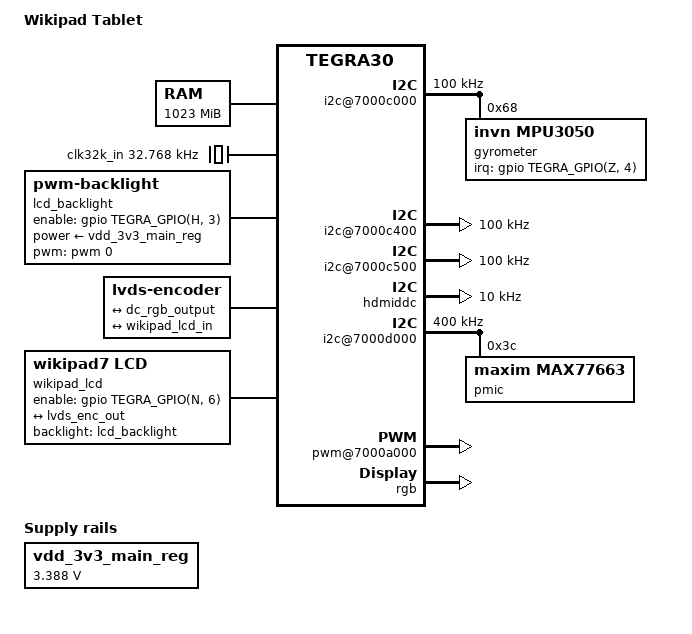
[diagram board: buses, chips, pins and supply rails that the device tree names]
// SPDX-License-Identifier: GPL-2.0
/dts-v1/;

#include "tegra30.dtsi"
#include <dt-bindings/mfd/max77620.h>
#include <dt-bindings/thermal/thermal.h>

/ {
	model = "Wikipad Tablet";
	compatible = "nvidia,wikipad", "nvidia,tegra30";

//	aliases {
//		rtc0 = "/i2c@7000d000/tps65911@2d";
//		rtc1 = "/rtc@7000e000";
//		serial0 = &uarta;
//	};

	chosen {
//		bootargs = "boot_delay=1000";
//		stdout-path = "serial0:115200n8";
	};

	firmware {
		trusted-foundations {
			compatible = "tlm,trusted-foundations";
			tlm,version-major = <2>;
			tlm,version-minor = <8>;
		};
	};

	memory@80000000 {
		reg = <0x80000000 0x3ff00000>;		// mem=1022M@2048M
	};

	clocks {
		compatible = "simple-bus";
		#address-cells = <1>;
		#size-cells = <0>;

		clk32k_in: clock@0 {
			compatible = "fixed-clock";
			reg = <0>;
			#clock-cells = <0>;
			clock-frequency = <32768>;
		};
	};

//	pcie@3000 {
//		status = "okay";
//
//		avdd-pexa-supply = <&ldo1_reg>;
//		vdd-pexa-supply = <&ldo1_reg>;
//		avdd-pexb-supply = <&ldo1_reg>;
//		vdd-pexb-supply = <&ldo1_reg>;
//		avdd-pex-pll-supply = <&ldo1_reg>;
//		avdd-plle-supply = <&ldo1_reg>;
//		vddio-pex-ctl-supply = <&sys_3v3_reg>;
//		hvdd-pex-supply = <&sys_3v3_pexs_reg>;
//
//		pci@1,0 {
//			status = "okay";
//			nvidia,num-lanes = <2>;
//		};
//
//		pci@2,0 {
//			nvidia,num-lanes = <2>;
//		};
//
//		pci@3,0 {
//			status = "okay";
//			nvidia,num-lanes = <2>;
//		};
//	};

// Copied from board-nabi2-pinmux
///////////////////////////////////
	pinmux@70000868 {
		pinctrl-names = "default";
		pinctrl-0 = <&state_default>;

		state_default: pinmux {
// SFIO
///////////////////////////////////
// SDMMC
////////////////
			sdmmc1_clk_pz0 {					// SD card slot
				nvidia,pins = "sdmmc1_clk_pz0";
				nvidia,function = "sdmmc1";
				nvidia,pull = <TEGRA_PIN_PULL_NONE>;
				nvidia,tristate = <TEGRA_PIN_DISABLE>;
				nvidia,enable-input = <TEGRA_PIN_ENABLE>;
			};
			sdmmc1_dat3_py4 {
				nvidia,pins = "sdmmc1_dat3_py4",
						"sdmmc1_dat2_py5",
						"sdmmc1_dat1_py6",
						"sdmmc1_dat0_py7",
						"sdmmc1_cmd_pz1";
				nvidia,function = "sdmmc1";
				nvidia,pull = <TEGRA_PIN_PULL_UP>;
				nvidia,tristate = <TEGRA_PIN_DISABLE>;
				nvidia,enable-input = <TEGRA_PIN_ENABLE>;
			};
			sdmmc3_clk_pa6 {					// Broadcom WLAN SDIO card
				nvidia,pins = "sdmmc3_clk_pa6";
				nvidia,function = "sdmmc3";
				nvidia,pull = <TEGRA_PIN_PULL_NONE>;
				nvidia,tristate = <TEGRA_PIN_DISABLE>;
				nvidia,enable-input = <TEGRA_PIN_ENABLE>;
			};
			sdmmc3_cmd_pa7 {
				nvidia,pins = "sdmmc3_cmd_pa7",
						"sdmmc3_dat0_pb7",
						"sdmmc3_dat1_pb6",
						"sdmmc3_dat2_pb5",
						"sdmmc3_dat3_pb4",
						"sdmmc3_dat6_pd3",
						"sdmmc3_dat7_pd4";		// GPIO: wlan_rst
				nvidia,function = "sdmmc3";
				nvidia,pull = <TEGRA_PIN_PULL_UP>;
				nvidia,tristate = <TEGRA_PIN_DISABLE>;
				nvidia,enable-input = <TEGRA_PIN_ENABLE>;
			};
			sdmmc4_clk_pcc4 {					// SSD
				nvidia,pins = "sdmmc4_clk_pcc4";
				nvidia,function = "sdmmc4";
				nvidia,pull = <TEGRA_PIN_PULL_NONE>;
				nvidia,tristate = <TEGRA_PIN_DISABLE>;
				nvidia,enable-input = <TEGRA_PIN_ENABLE>;
			};
			sdmmc4_rst_n_pcc3 {
				nvidia,pins = "sdmmc4_rst_n_pcc3";
				nvidia,function = "rsvd2";
				nvidia,pull = <TEGRA_PIN_PULL_DOWN>;
				nvidia,tristate = <TEGRA_PIN_DISABLE>;
				nvidia,enable-input = <TEGRA_PIN_ENABLE>;
			};
			sdmmc4_cmd_pt7 {
				nvidia,pins = "sdmmc4_cmd_pt7",
						"sdmmc4_dat0_paa0",
						"sdmmc4_dat1_paa1",
						"sdmmc4_dat2_paa2",
						"sdmmc4_dat3_paa3",
						"sdmmc4_dat4_paa4",
						"sdmmc4_dat5_paa5",
						"sdmmc4_dat6_paa6",
						"sdmmc4_dat7_paa7";
				nvidia,function = "sdmmc4";
				nvidia,pull = <TEGRA_PIN_PULL_UP>;
				nvidia,tristate = <TEGRA_PIN_DISABLE>;
				nvidia,enable-input = <TEGRA_PIN_ENABLE>;
			};
// I2C
////////////////
			gen1_i2c_scl_pc4 {					// I2C 1
				nvidia,pins = "gen1_i2c_scl_pc4",
						"gen1_i2c_sda_pc5";
				nvidia,function = "i2c1";
				nvidia,pull = <TEGRA_PIN_PULL_NONE>;
				nvidia,tristate = <TEGRA_PIN_DISABLE>;
				nvidia,enable-input = <TEGRA_PIN_ENABLE>;
				nvidia,open-drain = <TEGRA_PIN_ENABLE>;
			};
			gen2_i2c_scl_pt5 {					// I2C 2
				nvidia,pins = "gen2_i2c_scl_pt5",
						"gen2_i2c_sda_pt6";
				nvidia,function = "i2c2";
				nvidia,pull = <TEGRA_PIN_PULL_NONE>;
				nvidia,tristate = <TEGRA_PIN_DISABLE>;
				nvidia,enable-input = <TEGRA_PIN_ENABLE>;
				nvidia,open-drain = <TEGRA_PIN_ENABLE>;
			};
			cam_i2c_scl_pbb1 {					// I2C 3
				nvidia,pins = "cam_i2c_scl_pbb1",
						"cam_i2c_sda_pbb2";
				nvidia,function = "i2c3";
				nvidia,pull = <TEGRA_PIN_PULL_NONE>;
				nvidia,tristate = <TEGRA_PIN_DISABLE>;
				nvidia,enable-input = <TEGRA_PIN_ENABLE>;
				nvidia,open-drain = <TEGRA_PIN_ENABLE>;
			};
			ddc_scl_pv4 {						// I2C 4
				nvidia,pins = "ddc_scl_pv4",
						"ddc_sda_pv5";
				nvidia,function = "i2c4";
				nvidia,pull = <TEGRA_PIN_PULL_NONE>;
				nvidia,tristate = <TEGRA_PIN_DISABLE>;
				nvidia,enable-input = <TEGRA_PIN_ENABLE>;
				//nvidia,open-drain = <TEGRA_PIN_ENABLE>;	// I2C without open-drain????
			};
			pwr_i2c_scl_pz6 {					// I2C power
				nvidia,pins = "pwr_i2c_scl_pz6",
						"pwr_i2c_sda_pz7";
				nvidia,function = "i2cpwr";
				nvidia,pull = <TEGRA_PIN_PULL_NONE>;
				nvidia,tristate = <TEGRA_PIN_DISABLE>;
				nvidia,enable-input = <TEGRA_PIN_ENABLE>;
				nvidia,open-drain = <TEGRA_PIN_ENABLE>;
			};
// LCD
////////////////
			lcd_pclk_pb3 {
				nvidia,pins = "lcd_pclk_pb3",
						"lcd_de_pj1",
						"lcd_hsync_pj3",
						"lcd_vsync_pj4",
						"lcd_d0_pe0",
						"lcd_d1_pe1",
						"lcd_d2_pe2",
						"lcd_d3_pe3",
						"lcd_d4_pe4",
						"lcd_d5_pe5",
						"lcd_d6_pe6",
						"lcd_d7_pe7",
						"lcd_d8_pf0",
						"lcd_d9_pf1",
						"lcd_d10_pf2",
						"lcd_d11_pf3",
						"lcd_d12_pf4",
						"lcd_d13_pf5",
						"lcd_d14_pf6",
						"lcd_d15_pf7",
						"lcd_d16_pm0",
						"lcd_d17_pm1",
						"lcd_d18_pm2",
						"lcd_d19_pm3",
						"lcd_d20_pm4",
						"lcd_d21_pm5",
						"lcd_d22_pm6",
						"lcd_d23_pm7";
				nvidia,function = "displaya";
				nvidia,pull = <TEGRA_PIN_PULL_NONE>;
				nvidia,tristate = <TEGRA_PIN_DISABLE>;
				nvidia,enable-input = <TEGRA_PIN_ENABLE>;
			};
// Serial
////////////////
			uart2_txd_pc2 {						// UARTB (GPS)
				nvidia,pins = "uart2_txd_pc2",
						"uart2_rts_n_pj6";
				nvidia,function = "uartb";
				nvidia,pull = <TEGRA_PIN_PULL_NONE>;
				nvidia,tristate = <TEGRA_PIN_DISABLE>;
				nvidia,enable-input = <TEGRA_PIN_DISABLE>;
			};
			uart2_rxd_pc3 {
				nvidia,pins = "uart2_rxd_pc3",
						"uart2_cts_n_pj5";
				nvidia,function = "uartb";
				nvidia,pull = <TEGRA_PIN_PULL_NONE>;
				nvidia,tristate = <TEGRA_PIN_DISABLE>;
				nvidia,enable-input = <TEGRA_PIN_ENABLE>;
			};
			uart3_cts_n_pa1 {					// UARTC (BT)
				nvidia,pins = "uart3_cts_n_pa1",
						"uart3_rxd_pw7";
				nvidia,function = "uartc";
				nvidia,pull = <TEGRA_PIN_PULL_NONE>;
				nvidia,tristate = <TEGRA_PIN_DISABLE>;
				nvidia,enable-input = <TEGRA_PIN_ENABLE>;
			};
			uart3_rts_n_pc0 {
				nvidia,pins = "uart3_rts_n_pc0",
						"uart3_txd_pw6";
				nvidia,function = "uartc";
				nvidia,pull = <TEGRA_PIN_PULL_NONE>;
				nvidia,tristate = <TEGRA_PIN_DISABLE>;
				nvidia,enable-input = <TEGRA_PIN_DISABLE>;
			};
			gmi_a17_pb0 {						// UARTD (debug)
				nvidia,pins = "gmi_a17_pb0";
				nvidia,function = "uartd";
				nvidia,pull = <TEGRA_PIN_PULL_NONE>;
				nvidia,tristate = <TEGRA_PIN_DISABLE>;
				nvidia,enable-input = <TEGRA_PIN_ENABLE>;
			};
			gmi_a16_pj7 {
				nvidia,pins = "gmi_a16_pj7";
				nvidia,function = "uartd";
				nvidia,pull = <TEGRA_PIN_PULL_NONE>;
				nvidia,tristate = <TEGRA_PIN_DISABLE>;
				nvidia,enable-input = <TEGRA_PIN_DISABLE>;
			};
// KBC
////////////////
			kb_col0_pq0 {
				nvidia,pins = "kb_col0_pq0",
						"kb_col1_pq1",
						"kb_col2_pq2",
						"kb_col3_pq3",
						"kb_row0_pr0",			// KEY_VOLUMEUP
						"kb_row1_pr1",			// KEY_VOLUMEDOWN
						"kb_row2_pr2";
				nvidia,function = "kbc";
				nvidia,pull = <TEGRA_PIN_PULL_UP>;
				nvidia,tristate = <TEGRA_PIN_DISABLE>;
				nvidia,enable-input = <TEGRA_PIN_ENABLE>;
			};
// I2S
////////////////
			dap1_fs_pn0 {						// I2S0 (Modem)
				nvidia,pins = "dap1_fs_pn0",
						"dap1_din_pn1",
						"dap1_dout_pn2",
						"dap1_sclk_pn3";
				nvidia,function = "i2s0";
				nvidia,pull = <TEGRA_PIN_PULL_NONE>;
				nvidia,tristate = <TEGRA_PIN_DISABLE>;
				nvidia,enable-input = <TEGRA_PIN_ENABLE>;
			};
			dap2_fs_pa2 {						// I2S1 (Codec)
				nvidia,pins = "dap2_fs_pa2",
						"dap2_din_pa4",
						"dap2_dout_pa5",
						"dap2_sclk_pa3";
				nvidia,function = "i2s1";
				nvidia,pull = <TEGRA_PIN_PULL_NONE>;
				nvidia,tristate = <TEGRA_PIN_DISABLE>;
				nvidia,enable-input = <TEGRA_PIN_ENABLE>;
			};
			dap4_fs_pp4 {						// I2S3 (BT)
				nvidia,pins = "dap4_fs_pp4",
						"dap4_din_pp5",
						"dap4_dout_pp6",
						"dap4_sclk_pp7";
				nvidia,function = "i2s3";
				nvidia,pull = <TEGRA_PIN_PULL_NONE>;
				nvidia,tristate = <TEGRA_PIN_DISABLE>;
				nvidia,enable-input = <TEGRA_PIN_ENABLE>;
			};
// SPI
////////////////
			spi1_mosi_px4 {						// SPI1 (Touch)
				nvidia,pins = "spi1_mosi_px4",
						"spi1_sck_px5",
						"spi1_cs0_n_px6",
						"spi1_miso_px7";
				nvidia,function = "spi1";
				nvidia,pull = <TEGRA_PIN_PULL_NONE>;
				nvidia,tristate = <TEGRA_PIN_DISABLE>;
				nvidia,enable-input = <TEGRA_PIN_ENABLE>;
			};
// SPDIF
////////////////
			spdif_out_pk5 {
				nvidia,pins = "spdif_out_pk5";
				nvidia,function = "spdif";
				nvidia,pull = <TEGRA_PIN_PULL_NONE>;
				nvidia,tristate = <TEGRA_PIN_DISABLE>;
				nvidia,enable-input = <TEGRA_PIN_DISABLE>;
			};
			spdif_in_pk6 {
				nvidia,pins = "spdif_in_pk6";
				nvidia,function = "spdif";
				nvidia,pull = <TEGRA_PIN_PULL_NONE>;
				nvidia,tristate = <TEGRA_PIN_DISABLE>;
				nvidia,enable-input = <TEGRA_PIN_ENABLE>;
			};
// Fixed func
////////////////
			clk_32k_out_pa0 {
				nvidia,pins = "clk_32k_out_pa0";
				nvidia,function = "blink";
				nvidia,pull = <TEGRA_PIN_PULL_NONE>;
				nvidia,tristate = <TEGRA_PIN_DISABLE>;
				nvidia,enable-input = <TEGRA_PIN_DISABLE>;
			};
			sys_clk_req_pz5 {
				nvidia,pins = "sys_clk_req_pz5";
				nvidia,function = "sysclk";
				nvidia,pull = <TEGRA_PIN_PULL_NONE>;
				nvidia,tristate = <TEGRA_PIN_DISABLE>;
				nvidia,enable-input = <TEGRA_PIN_DISABLE>;
			};
			owr {
				nvidia,pins = "owr";
				nvidia,function = "rsvd3";
				nvidia,pull = <TEGRA_PIN_PULL_NONE>;
				nvidia,tristate = <TEGRA_PIN_DISABLE>;
				nvidia,enable-input = <TEGRA_PIN_ENABLE>;
			};
			gmi_ad4_pg4 {						// TEGRA_GPIO_PG4
				nvidia,pins = "gmi_ad4_pg4";
				nvidia,function = "rsvd1";
				nvidia,pull = <TEGRA_PIN_PULL_NONE>;
				nvidia,tristate = <TEGRA_PIN_DISABLE>;
				nvidia,enable-input = <TEGRA_PIN_ENABLE>;
			};
			clk1_out_pw4 {
				nvidia,pins = "clk1_out_pw4";
				nvidia,function = "extperiph1";
				nvidia,pull = <TEGRA_PIN_PULL_NONE>;
				nvidia,tristate = <TEGRA_PIN_DISABLE>;
				nvidia,enable-input = <TEGRA_PIN_ENABLE>;
			};
			clk2_out_pw5 {
				nvidia,pins = "clk2_out_pw5";
				nvidia,function = "extperiph2";
				nvidia,pull = <TEGRA_PIN_PULL_NONE>;
				nvidia,tristate = <TEGRA_PIN_DISABLE>;
				nvidia,enable-input = <TEGRA_PIN_ENABLE>;
			};
			clk3_out_pee0 {
				nvidia,pins = "clk3_out_pee0";
				nvidia,function = "extperiph3";
				nvidia,pull = <TEGRA_PIN_PULL_NONE>;
				nvidia,tristate = <TEGRA_PIN_DISABLE>;
				nvidia,enable-input = <TEGRA_PIN_DISABLE>;
			};
			clk2_req_pcc5 {
				nvidia,pins = "clk2_req_pcc5";
				nvidia,function = "dap";
				nvidia,pull = <TEGRA_PIN_PULL_NONE>;
				nvidia,tristate = <TEGRA_PIN_DISABLE>;
				nvidia,enable-input = <TEGRA_PIN_ENABLE>;
			};
			hdmi_int_pn7 {						// hdmi_hpd
				nvidia,pins = "hdmi_int_pn7";
				nvidia,function = "hdmi";
				nvidia,pull = <TEGRA_PIN_PULL_NONE>;
				nvidia,tristate = <TEGRA_PIN_ENABLE>;
				nvidia,enable-input = <TEGRA_PIN_ENABLE>;
			};

// GPIO
///////////////////////////////////
// Power
////////////////
			dap3_fs_pp0 {
				nvidia,pins = "dap3_fs_pp0";
				nvidia,function = "i2s2";
				nvidia,pull = <TEGRA_PIN_PULL_NONE>;
				nvidia,tristate = <TEGRA_PIN_DISABLE>;
				nvidia,enable-input = <TEGRA_PIN_DISABLE>;
			};
			sdmmc3_dat5_pd0 {		
				nvidia,pins = "sdmmc3_dat5_pd0";		// bt_rfkill_rese
				nvidia,function = "sdmmc3";
				nvidia,pull = <TEGRA_PIN_PULL_NONE>;
				nvidia,tristate = <TEGRA_PIN_DISABLE>;
				nvidia,enable-input = <TEGRA_PIN_DISABLE>;
			};
			kb_row6_pr6 {			
				nvidia,pins = "kb_row6_pr6",			// fixed_reg_en_cam1_ld
						"kb_row7_pr7",
						"kb_row8_ps0";			// fixed_reg_en_1v8_cam
				nvidia,function = "kbc";
				nvidia,pull = <TEGRA_PIN_PULL_NONE>;
				nvidia,tristate = <TEGRA_PIN_DISABLE>;
				nvidia,enable-input = <TEGRA_PIN_DISABLE>;
			};
			lcd_m1_pw1 {			
				nvidia,pins = "lcd_m1_pw1",			// vdd_lvds_dreg
						"lcd_pwr0_pb2",			// fixed_reg_en_vddio_v
						"lcd_pwr1_pc1",			// fixed_reg_en_3v3_fus
						"lcd_pwr2_pc6";			// fixed_reg_en_vdd_sdm
				nvidia,function = "displaya";
				nvidia,pull = <TEGRA_PIN_PULL_NONE>;
				nvidia,tristate = <TEGRA_PIN_DISABLE>;
				nvidia,enable-input = <TEGRA_PIN_DISABLE>;
			};
			gmi_ad10_ph2 {						// vdd_lvds_areg
				nvidia,pins = "gmi_ad10_ph2";
				nvidia,function = "pwm2";
				nvidia,pull = <TEGRA_PIN_PULL_NONE>;
				nvidia,tristate = <TEGRA_PIN_DISABLE>;
				nvidia,enable-input = <TEGRA_PIN_DISABLE>;
			};

// Camera
////////////////
			cam_mclk_pcc0 {
				nvidia,pins = "cam_mclk_pcc0";
				nvidia,function = "vi_alt3";			// Boardfile wrong???
				nvidia,pull = <TEGRA_PIN_PULL_UP>;
				nvidia,tristate = <TEGRA_PIN_DISABLE>;
				nvidia,enable-input = <TEGRA_PIN_ENABLE>;
			};
			pbb0 {
				nvidia,pins = "pbb0",				// hm2057_reset
						"pcc1";
				nvidia,function = "rsvd2";
				nvidia,pull = <TEGRA_PIN_PULL_NONE>;
				nvidia,tristate = <TEGRA_PIN_DISABLE>;
				nvidia,enable-input = <TEGRA_PIN_ENABLE>;
			};
			pbb3 {
				nvidia,pins = "pbb3";
				nvidia,function = "vgp3";
				nvidia,pull = <TEGRA_PIN_PULL_NONE>;
				nvidia,tristate = <TEGRA_PIN_DISABLE>;
				nvidia,enable-input = <TEGRA_PIN_ENABLE>;
			};
			pbb5 {							// hm2057_pwdn
				nvidia,pins = "pbb5";
				nvidia,function = "vgp5";
				nvidia,pull = <TEGRA_PIN_PULL_UP>;
				nvidia,tristate = <TEGRA_PIN_DISABLE>;
				nvidia,enable-input = <TEGRA_PIN_ENABLE>;
			};
			pbb6 {
				nvidia,pins = "pbb6";
				nvidia,function = "vgp6";
				nvidia,pull = <TEGRA_PIN_PULL_NONE>;
				nvidia,tristate = <TEGRA_PIN_DISABLE>;
				nvidia,enable-input = <TEGRA_PIN_ENABLE>;
			};
			pbb7 {
				nvidia,pins = "pbb7",
						"pcc2";
				nvidia,function = "i2s4";
				nvidia,pull = <TEGRA_PIN_PULL_NONE>;
				nvidia,tristate = <TEGRA_PIN_DISABLE>;
				nvidia,enable-input = <TEGRA_PIN_ENABLE>;
			};
			kb_row4_pr4 {
				nvidia,pins = "kb_row4_pr4",
						"kb_row5_pr5",
						"kb_row9_ps1",
						"kb_row10_ps2";
				nvidia,function = "kbc";
				nvidia,pull = <TEGRA_PIN_PULL_NONE>;
				nvidia,tristate = <TEGRA_PIN_DISABLE>;
				nvidia,enable-input = <TEGRA_PIN_DISABLE>;
			};
			vi_d2_pl0 {
				nvidia,pins = "vi_d2_pl0",
						"vi_d3_pl1",
						"vi_d4_pl2",
						"vi_d5_pl3",
						"vi_d6_pl4",
						"vi_d7_pl5",
						"vi_d8_pl6",
						"vi_d9_pl7",
						"vi_hsync_pd7",
						"vi_vsync_pd6",
						"vi_pclk_pt0",
						"vi_mclk_pt1";
				nvidia,function = "vi";
				nvidia,pull = <TEGRA_PIN_PULL_NONE>;
				nvidia,tristate = <TEGRA_PIN_DISABLE>;
				nvidia,enable-input = <TEGRA_PIN_ENABLE>;
//				nvidia,io-reset = <0>;
			};
// Modem
////////////////
			pv0 {
				nvidia,pins = "pv0",
						"pv1";
				nvidia,function = "rsvd1";
				nvidia,pull = <TEGRA_PIN_PULL_NONE>;
				nvidia,tristate = <TEGRA_PIN_DISABLE>;
				nvidia,enable-input = <TEGRA_PIN_ENABLE>;
			};
// GPS & BT
////////////////
			pu0 {
				nvidia,pins = "pu0",
						"pu1";				// bt_ext_wake
				nvidia,function = "rsvd4";
				nvidia,pull = <TEGRA_PIN_PULL_NONE>;
				nvidia,tristate = <TEGRA_PIN_DISABLE>;
				nvidia,enable-input = <TEGRA_PIN_DISABLE>;
			};
			pu2 {			
				nvidia,pins = "pu2",				// sysfs
						"pu3",				// sysfs
						"pu6";				// bt_host_wake
				nvidia,function = "rsvd4";
				nvidia,pull = <TEGRA_PIN_PULL_NONE>;
				nvidia,tristate = <TEGRA_PIN_DISABLE>;
				nvidia,enable-input = <TEGRA_PIN_ENABLE>;
			};
			pu4 {
				nvidia,pins = "pu4";
				nvidia,function = "pwm1";
				nvidia,pull = <TEGRA_PIN_PULL_NONE>;
				nvidia,tristate = <TEGRA_PIN_DISABLE>;
				nvidia,enable-input = <TEGRA_PIN_DISABLE>;
			};
			pu5 {							// bcmsdh_sdmmc
				nvidia,pins = "pu5";
				nvidia,function = "pwm2";
				nvidia,pull = <TEGRA_PIN_PULL_DOWN>;
				nvidia,tristate = <TEGRA_PIN_DISABLE>;
				nvidia,enable-input = <TEGRA_PIN_ENABLE>;
			};
			kb_row14_ps6 {
				nvidia,pins = "kb_row14_ps6";
				nvidia,function = "kbc";
				nvidia,pull = <TEGRA_PIN_PULL_NONE>;
				nvidia,tristate = <TEGRA_PIN_ENABLE>;
				nvidia,enable-input = <TEGRA_PIN_DISABLE>;
			};
// LCD
////////////////
			gmi_ad0_pg0 {
				nvidia,pins = "gmi_ad0_pg0",
						"gmi_ad1_pg1";
				nvidia,function = "rsvd1";
				nvidia,pull = <TEGRA_PIN_PULL_NONE>;
				nvidia,tristate = <TEGRA_PIN_DISABLE>;
				nvidia,enable-input = <TEGRA_PIN_DISABLE>;
			};
			gmi_ad2_pg2 {
				nvidia,pins = "gmi_ad2_pg2",
						"gmi_ad3_pg3",
						"gmi_ad6_pg6",
						"gmi_ad7_pg7";
				nvidia,function = "rsvd1";
				nvidia,pull = <TEGRA_PIN_PULL_DOWN>;
				nvidia,tristate = <TEGRA_PIN_DISABLE>;
				nvidia,enable-input = <TEGRA_PIN_DISABLE>;
			};
			gmi_ad5_pg5 {						// TEGRA_GPIO_PG5
				nvidia,pins = "gmi_ad5_pg5";
				nvidia,function = "rsvd1";
				nvidia,pull = <TEGRA_PIN_PULL_NONE>;
				nvidia,tristate = <TEGRA_PIN_DISABLE>;
				nvidia,enable-input = <TEGRA_PIN_ENABLE>;
			};
			gmi_ad9_ph1 {						// otg_gpio
				nvidia,pins = "gmi_ad9_ph1";
				nvidia,function = "rsvd4";
				nvidia,pull = <TEGRA_PIN_PULL_DOWN>;
				nvidia,tristate = <TEGRA_PIN_DISABLE>;
				nvidia,enable-input = <TEGRA_PIN_DISABLE>;
			};
			lcd_dc0_pn6 {						// LVDS Encoder Shutdown
				nvidia,pins = "lcd_dc0_pn6";
				nvidia,function = "displaya";
				nvidia,pull = <TEGRA_PIN_PULL_NONE>;
				nvidia,tristate = <TEGRA_PIN_DISABLE>;
				nvidia,enable-input = <TEGRA_PIN_DISABLE>;
			};
			gmi_ad8_ph0 {						// Backlight PWM
				nvidia,pins = "gmi_ad8_ph0";
				nvidia,function = "pwm0";
				nvidia,pull = <TEGRA_PIN_PULL_NONE>;
				nvidia,tristate = <TEGRA_PIN_DISABLE>;
				nvidia,enable-input = <TEGRA_PIN_DISABLE>;
			};
			gmi_ad11_ph3 {						// Backlight Enable
				nvidia,pins = "gmi_ad11_ph3";
				nvidia,function = "pwm3";
				nvidia,pull = <TEGRA_PIN_PULL_NONE>;
				nvidia,tristate = <TEGRA_PIN_DISABLE>;
				nvidia,enable-input = <TEGRA_PIN_DISABLE>;
			};
// Touch
////////////////
			gmi_a19_pk7 {						// tp_rst
				nvidia,pins = "gmi_a19_pk7";
				nvidia,function = "gmi";
				nvidia,pull = <TEGRA_PIN_PULL_NONE>;
				nvidia,tristate = <TEGRA_PIN_DISABLE>;
				nvidia,enable-input = <TEGRA_PIN_DISABLE>;
			};
			gmi_cs0_n_pj0 {
				nvidia,pins = "gmi_cs0_n_pj0",			// tp_int
						"gmi_ad12_ph4",			// tp_detect
						"gmi_ad13_ph5",			// tp_detect0
						"gmi_ad14_ph6",			// tp_detect1
						"gmi_ad15_ph7";			// tp_detect2
				nvidia,function = "rsvd1";
				nvidia,pull = <TEGRA_PIN_PULL_NONE>;
				nvidia,tristate = <TEGRA_PIN_DISABLE>;
				nvidia,enable-input = <TEGRA_PIN_ENABLE>;
			};
			gmi_wait_pi7 {
				nvidia,pins = "gmi_wait_pi7",
						"gmi_wp_n_pc7";
				nvidia,function = "rsvd1";
				nvidia,pull = <TEGRA_PIN_PULL_UP>;
				nvidia,tristate = <TEGRA_PIN_DISABLE>;
				nvidia,enable-input = <TEGRA_PIN_ENABLE>;
			};
			lcd_sdout_pn5 {
				nvidia,pins = "lcd_sdout_pn5",			// tp_int18
						"lcd_dc1_pd2";
				nvidia,function = "displaya";
				nvidia,pull = <TEGRA_PIN_PULL_NONE>;
				nvidia,tristate = <TEGRA_PIN_DISABLE>;
				nvidia,enable-input = <TEGRA_PIN_ENABLE>;
			};
			lcd_wr_n_pz3 {
				nvidia,pins = "lcd_wr_n_pz3";			// tp_rst18
				nvidia,function = "displaya";
				nvidia,pull = <TEGRA_PIN_PULL_UP>;
				nvidia,tristate = <TEGRA_PIN_DISABLE>;
				nvidia,enable-input = <TEGRA_PIN_ENABLE>;
			};
// SDMMC
////////////////
			gmi_iordy_pi5 {						// sdhci_cd
				nvidia,pins = "gmi_iordy_pi5";
				nvidia,function = "rsvd1";
				nvidia,pull = <TEGRA_PIN_PULL_UP>;
				nvidia,tristate = <TEGRA_PIN_DISABLE>;
				nvidia,enable-input = <TEGRA_PIN_ENABLE>;
			};
// Codec
////////////////
			spi2_sck_px2 {						// reset_en
				nvidia,pins = "spi2_sck_px2";
				nvidia,function = "spi2";
				nvidia,pull = <TEGRA_PIN_PULL_NONE>;
				nvidia,tristate = <TEGRA_PIN_DISABLE>;
				nvidia,enable-input = <TEGRA_PIN_DISABLE>;
			};
			spi2_mosi_px0 {
				nvidia,pins = "spi2_mosi_px0",
						"spi2_miso_px1",
						"spi2_cs1_n_pw2",		// headphone detect
						"spi2_cs2_n_pw3";
				nvidia,function = "spi2";
				nvidia,pull = <TEGRA_PIN_PULL_NONE>;
				nvidia,tristate = <TEGRA_PIN_DISABLE>;
				nvidia,enable-input = <TEGRA_PIN_ENABLE>;
			};
			gmi_cs2_n_pk3 {
				nvidia,pins = "gmi_cs2_n_pk3";
				nvidia,function = "rsvd1";
				nvidia,pull = <TEGRA_PIN_PULL_UP>;
				nvidia,tristate = <TEGRA_PIN_DISABLE>;
				nvidia,enable-input = <TEGRA_PIN_DISABLE>;
			};
			gmi_cs3_n_pk4 {
				nvidia,pins = "gmi_cs3_n_pk4";
				nvidia,function = "rsvd1";
				nvidia,pull = <TEGRA_PIN_PULL_NONE>;
				nvidia,tristate = <TEGRA_PIN_DISABLE>;
				nvidia,enable-input = <TEGRA_PIN_DISABLE>;
			};
			gmi_a18_pb1 {						// spkr_en
				nvidia,pins = "gmi_a18_pb1";
				nvidia,function = "spi4";
				nvidia,pull = <TEGRA_PIN_PULL_NONE>;
				nvidia,tristate = <TEGRA_PIN_DISABLE>;
				nvidia,enable-input = <TEGRA_PIN_DISABLE>;
			};
// Sensors
////////////////
			lcd_sck_pz4 {
				nvidia,pins = "lcd_sck_pz4";			// mpu3050
				nvidia,function = "displaya";
				nvidia,pull = <TEGRA_PIN_PULL_NONE>;
				nvidia,tristate = <TEGRA_PIN_DISABLE>;
				nvidia,enable-input = <TEGRA_PIN_ENABLE>;
			};
// Others
////////////////
			kb_row3_pr3 {
				nvidia,pins = "kb_row3_pr3";
				nvidia,function = "kbc";
				nvidia,pull = <TEGRA_PIN_PULL_NONE>;
				nvidia,tristate = <TEGRA_PIN_DISABLE>;
				nvidia,enable-input = <TEGRA_PIN_DISABLE>;
			};
			gmi_dqs_pi2 {
				nvidia,pins = "gmi_dqs_pi2";
				nvidia,function = "rsvd1";
				nvidia,pull = <TEGRA_PIN_PULL_NONE>;
				nvidia,tristate = <TEGRA_PIN_DISABLE>;
				nvidia,enable-input = <TEGRA_PIN_ENABLE>;
			};
			gmi_clk_pk1 {
				nvidia,pins = "gmi_clk_pk1";
				nvidia,function = "rsvd1";
				nvidia,pull = <TEGRA_PIN_PULL_UP>;
				nvidia,tristate = <TEGRA_PIN_DISABLE>;
				nvidia,enable-input = <TEGRA_PIN_ENABLE>;
			};
			gmi_rst_n_pi4 {
				nvidia,pins = "gmi_rst_n_pi4";
				nvidia,function = "nand";
				nvidia,pull = <TEGRA_PIN_PULL_UP>;
				nvidia,tristate = <TEGRA_PIN_DISABLE>;
				nvidia,enable-input = <TEGRA_PIN_DISABLE>;
			};
			lcd_cs0_n_pn4 {
				nvidia,pins = "lcd_cs0_n_pn4";
				nvidia,function = "displaya";
				nvidia,pull = <TEGRA_PIN_PULL_NONE>;
				nvidia,tristate = <TEGRA_PIN_DISABLE>;
				nvidia,enable-input = <TEGRA_PIN_ENABLE>;
			};
			lcd_cs1_n_pw0 {
				nvidia,pins = "lcd_cs1_n_pw0";
				nvidia,function = "displaya";
				nvidia,pull = <TEGRA_PIN_PULL_NONE>;
				nvidia,tristate = <TEGRA_PIN_DISABLE>;
				nvidia,enable-input = <TEGRA_PIN_ENABLE>;
			};
			lcd_sdin_pz2 {
				nvidia,pins = "lcd_sdin_pz2";
				nvidia,function = "displaya";
				nvidia,pull = <TEGRA_PIN_PULL_NONE>;
				nvidia,tristate = <TEGRA_PIN_DISABLE>;
				nvidia,enable-input = <TEGRA_PIN_ENABLE>;
			};
			crt_hsync_pv6 {
				nvidia,pins = "crt_hsync_pv6";
				nvidia,function = "crt";
				nvidia,pull = <TEGRA_PIN_PULL_NONE>;
				nvidia,tristate = <TEGRA_PIN_DISABLE>;
				nvidia,enable-input = <TEGRA_PIN_DISABLE>;
			};
			crt_vsync_pv7 {
				nvidia,pins = "crt_vsync_pv7";
				nvidia,function = "crt";
				nvidia,pull = <TEGRA_PIN_PULL_NONE>;
				nvidia,tristate = <TEGRA_PIN_DISABLE>;
				nvidia,enable-input = <TEGRA_PIN_DISABLE>;
			};
			pex_wake_n_pdd3 {
				nvidia,pins = "pex_wake_n_pdd3";
				nvidia,function = "pcie";
				nvidia,pull = <TEGRA_PIN_PULL_NONE>;
				nvidia,tristate = <TEGRA_PIN_DISABLE>;
				nvidia,enable-input = <TEGRA_PIN_ENABLE>;
			};
			pex_l2_prsnt_n_pdd7 {
				nvidia,pins = "pex_l2_prsnt_n_pdd7";
				nvidia,function = "pcie";
				nvidia,pull = <TEGRA_PIN_PULL_NONE>;
				nvidia,tristate = <TEGRA_PIN_DISABLE>;
				nvidia,enable-input = <TEGRA_PIN_ENABLE>;
			};
			pex_l2_rst_n_pcc6 {
				nvidia,pins = "pex_l2_rst_n_pcc6";
				nvidia,function = "pcie";
				nvidia,pull = <TEGRA_PIN_PULL_NONE>;
				nvidia,tristate = <TEGRA_PIN_DISABLE>;
				nvidia,enable-input = <TEGRA_PIN_DISABLE>;
			};
			pex_l2_clkreq_n_pcc7 {
				nvidia,pins = "pex_l2_clkreq_n_pcc7";
				nvidia,function = "pcie";
				nvidia,pull = <TEGRA_PIN_PULL_NONE>;
				nvidia,tristate = <TEGRA_PIN_DISABLE>;
				nvidia,enable-input = <TEGRA_PIN_DISABLE>;
			};
// Overridden later in the 'not used' section
//			hdmi_cec_pee3 {
//				nvidia,pins = "hdmi_cec_pee3";
//				nvidia,function = "cec";
//				nvidia,pull = <TEGRA_PIN_PULL_NONE>;
//				nvidia,tristate = <TEGRA_PIN_DISABLE>;
//				nvidia,enable-input = <TEGRA_PIN_ENABLE>;
//			};
			kb_row15_ps7 {
				nvidia,pins = "kb_row15_ps7";
				nvidia,function = "kbc";
				nvidia,pull = <TEGRA_PIN_PULL_NONE>;
				nvidia,tristate = <TEGRA_PIN_DISABLE>;
				nvidia,enable-input = <TEGRA_PIN_DISABLE>;
			};
			kb_row11_ps3 {						// temp_alert
				nvidia,pins = "kb_row11_ps3";
				nvidia,function = "kbc";
				nvidia,pull = <TEGRA_PIN_PULL_UP>;
				nvidia,tristate = <TEGRA_PIN_ENABLE>;
				nvidia,enable-input = <TEGRA_PIN_ENABLE>;
			};
			kb_row12_ps4 {
				nvidia,pins = "kb_row12_ps4";
				nvidia,function = "kbc";
				nvidia,pull = <TEGRA_PIN_PULL_NONE>;
				nvidia,tristate = <TEGRA_PIN_ENABLE>;
				nvidia,enable-input = <TEGRA_PIN_DISABLE>;
			};
			kb_row13_ps5 {
				nvidia,pins = "kb_row13_ps5";
				nvidia,function = "kbc";
				nvidia,pull = <TEGRA_PIN_PULL_NONE>;
				nvidia,tristate = <TEGRA_PIN_ENABLE>;
				nvidia,enable-input = <TEGRA_PIN_DISABLE>;
			};
			ulpi_dir_py1 {
				nvidia,pins = "ulpi_dir_py1";
				nvidia,function = "ulpi";
				nvidia,pull = <TEGRA_PIN_PULL_NONE>;
				nvidia,tristate = <TEGRA_PIN_DISABLE>;
				nvidia,enable-input = <TEGRA_PIN_DISABLE>;
			};
			ulpi_nxt_py2 {
				nvidia,pins = "ulpi_nxt_py2";
				nvidia,function = "ulpi";
				nvidia,pull = <TEGRA_PIN_PULL_NONE>;
				nvidia,tristate = <TEGRA_PIN_DISABLE>;
				nvidia,enable-input = <TEGRA_PIN_DISABLE>;
			};
			ulpi_stp_py3 {
				nvidia,pins = "ulpi_stp_py3";
				nvidia,function = "ulpi";
				nvidia,pull = <TEGRA_PIN_PULL_NONE>;
				nvidia,tristate = <TEGRA_PIN_DISABLE>;
				nvidia,enable-input = <TEGRA_PIN_DISABLE>;
			};
			gmi_cs4_n_pk2 {						// charge-bq24160
				nvidia,pins = "gmi_cs4_n_pk2";
				nvidia,function = "rsvd1";
				nvidia,pull = <TEGRA_PIN_PULL_NONE>;
				nvidia,tristate = <TEGRA_PIN_DISABLE>;
				nvidia,enable-input = <TEGRA_PIN_ENABLE>;
			};
			gmi_cs7_n_pi6 {						// GMI_CS7
				nvidia,pins = "gmi_cs7_n_pi6";			// Allegedly not used
				nvidia,function = "nand";
				nvidia,pull = <TEGRA_PIN_PULL_NONE>;
				nvidia,tristate = <TEGRA_PIN_ENABLE>;
				nvidia,enable-input = <TEGRA_PIN_DISABLE>;
			};
			gmi_cs1_n_pj2 {						// GMI_CS1
				nvidia,pins = "gmi_cs1_n_pj2";			// Allegedly not used
				nvidia,function = "rsvd1";
				nvidia,pull = <TEGRA_PIN_PULL_NONE>;
				nvidia,tristate = <TEGRA_PIN_ENABLE>;
				nvidia,enable-input = <TEGRA_PIN_DISABLE>;
			};
// Not used
////////////////
			ulpi_clk_py0 {
				nvidia,pins = "ulpi_clk_py0",
						"ulpi_data0_po1",
						"ulpi_data1_po2",
						"ulpi_data2_po3",
						"ulpi_data3_po4",
						"ulpi_data4_po5",
						"ulpi_data5_po6",
						"ulpi_data6_po7",
						"ulpi_data7_po0";
				nvidia,function = "ulpi";
				nvidia,pull = <TEGRA_PIN_PULL_NONE>;
				nvidia,tristate = <TEGRA_PIN_ENABLE>;
				nvidia,enable-input = <TEGRA_PIN_DISABLE>;
			};
			gmi_cs6_n_pi3 {
				nvidia,pins = "gmi_cs6_n_pi3";
				nvidia,function = "nand";
				nvidia,pull = <TEGRA_PIN_PULL_NONE>;
				nvidia,tristate = <TEGRA_PIN_ENABLE>;
				nvidia,enable-input = <TEGRA_PIN_DISABLE>;
			};
			kb_col4_pq4 {
				nvidia,pins = "kb_col4_pq4",
						"kb_col5_pq5",
						"kb_col6_pq6",
						"kb_col7_pq7";
				nvidia,function = "kbc";
				nvidia,pull = <TEGRA_PIN_PULL_NONE>;
				nvidia,tristate = <TEGRA_PIN_ENABLE>;
				nvidia,enable-input = <TEGRA_PIN_DISABLE>;
			};
			dap3_din_pp1 {
				nvidia,pins = "dap3_din_pp1",
						"dap3_dout_pp2",
						"dap3_sclk_pp3";
				nvidia,function = "rsvd2";
				nvidia,pull = <TEGRA_PIN_PULL_NONE>;
				nvidia,tristate = <TEGRA_PIN_ENABLE>;
				nvidia,enable-input = <TEGRA_PIN_DISABLE>;
			};
			clk1_req_pee2 {
				nvidia,pins = "clk1_req_pee2",
						"gmi_adv_n_pk0",
						"gmi_oe_n_pi1",
						"gmi_wr_n_pi0",
						"pex_l0_clkreq_n_pdd2",
						"pex_l0_prsnt_n_pdd0",
						"pex_l0_rst_n_pdd1",
						"pex_l1_clkreq_n_pdd6",
						"pex_l1_prsnt_n_pdd4",
						"pex_l1_rst_n_pdd5",
						"pv2",
						"pv3",
						"hdmi_cec_pee3",
						"clk3_req_pee1",
						"vi_d0_pt4",
						"vi_d1_pd5",
						"vi_d10_pt2",
						"vi_d11_pt3";
				nvidia,function = "rsvd4";
				nvidia,pull = <TEGRA_PIN_PULL_NONE>;
				nvidia,tristate = <TEGRA_PIN_ENABLE>;
				nvidia,enable-input = <TEGRA_PIN_DISABLE>;
			};
// Not listed!!!
////////////////
			sdmmc3_dat4_pd1 {
				nvidia,pins = "sdmmc3_dat4_pd1";
				nvidia,function = "sdmmc3";
				nvidia,pull = <TEGRA_PIN_PULL_UP>;
				nvidia,tristate = <TEGRA_PIN_ENABLE>;
				nvidia,enable-input = <TEGRA_PIN_ENABLE>;
			};
			jtag_rtck_pu7 {
				nvidia,pins = "jtag_rtck_pu7";
				nvidia,function = "rtck";
				nvidia,pull = <TEGRA_PIN_PULL_UP>;
				nvidia,tristate = <TEGRA_PIN_DISABLE>;
				nvidia,enable-input = <TEGRA_PIN_ENABLE>;
			};
			spi2_cs0_n_px3 {
				nvidia,pins = "spi2_cs0_n_px3";
				nvidia,function = "spi6";
				nvidia,pull = <TEGRA_PIN_PULL_UP>;
				nvidia,tristate = <TEGRA_PIN_DISABLE>;
				nvidia,enable-input = <TEGRA_PIN_ENABLE>;
			};
			pbb4 {
				nvidia,pins = "pbb4";
				nvidia,function = "vgp4";
				nvidia,pull = <TEGRA_PIN_PULL_NONE>;
				nvidia,tristate = <TEGRA_PIN_DISABLE>;
				nvidia,enable-input = <TEGRA_PIN_ENABLE>;
			};


// Pin group drive controls
//////////////////////////////
			drive_dap2 {
				nvidia,pins = "drive_dap2";
				nvidia,high-speed-mode = <TEGRA_PIN_DISABLE>;
				nvidia,schmitt = <TEGRA_PIN_ENABLE>;
				nvidia,low-power-mode = <3>;
				nvidia,pull-down-strength = <31>;
				nvidia,pull-up-strength = <31>;
				nvidia,slew-rate-rising = <TEGRA_PIN_SLEW_RATE_FASTEST>;
				nvidia,slew-rate-falling = <TEGRA_PIN_SLEW_RATE_FASTEST>;
			};
			drive_dbg {
				nvidia,pins = "drive_dbg";
				nvidia,high-speed-mode = <TEGRA_PIN_DISABLE>;
				nvidia,schmitt = <TEGRA_PIN_ENABLE>;
				nvidia,low-power-mode = <3>;
				nvidia,pull-down-strength = <31>;
				nvidia,pull-up-strength = <31>;
				nvidia,slew-rate-rising = <TEGRA_PIN_SLEW_RATE_FASTEST>;
				nvidia,slew-rate-falling = <TEGRA_PIN_SLEW_RATE_FASTEST>;
			};
			drive_at5 {
				nvidia,pins = "drive_at5";
				nvidia,high-speed-mode = <TEGRA_PIN_DISABLE>;
				nvidia,schmitt = <TEGRA_PIN_ENABLE>;
				nvidia,low-power-mode = <3>;
				nvidia,pull-down-strength = <31>;
				nvidia,pull-up-strength = <31>;
				nvidia,slew-rate-rising = <TEGRA_PIN_SLEW_RATE_FASTEST>;
				nvidia,slew-rate-falling = <TEGRA_PIN_SLEW_RATE_FASTEST>;
			};
			drive_gme {
				nvidia,pins = "drive_gme";
				nvidia,high-speed-mode = <TEGRA_PIN_DISABLE>;
				nvidia,schmitt = <TEGRA_PIN_ENABLE>;
				nvidia,low-power-mode = <3>;
				nvidia,pull-down-strength = <31>;
				nvidia,pull-up-strength = <31>;
				nvidia,slew-rate-rising = <TEGRA_PIN_SLEW_RATE_FASTEST>;
				nvidia,slew-rate-falling = <TEGRA_PIN_SLEW_RATE_FASTEST>;
			};
			drive_ddc {
				nvidia,pins = "drive_ddc";
				nvidia,high-speed-mode = <TEGRA_PIN_DISABLE>;
				nvidia,schmitt = <TEGRA_PIN_ENABLE>;
				nvidia,low-power-mode = <3>;
				nvidia,pull-down-strength = <31>;
				nvidia,pull-up-strength = <31>;
				nvidia,slew-rate-rising = <TEGRA_PIN_SLEW_RATE_FASTEST>;
				nvidia,slew-rate-falling = <TEGRA_PIN_SLEW_RATE_FASTEST>;
			};
			drive_ao1 {
				nvidia,pins = "drive_ao1";
				nvidia,high-speed-mode = <TEGRA_PIN_DISABLE>;
				nvidia,schmitt = <TEGRA_PIN_ENABLE>;
				nvidia,low-power-mode = <3>;
				nvidia,pull-down-strength = <31>;
				nvidia,pull-up-strength = <31>;
				nvidia,slew-rate-rising = <TEGRA_PIN_SLEW_RATE_FASTEST>;
				nvidia,slew-rate-falling = <TEGRA_PIN_SLEW_RATE_FASTEST>;
			};
			drive_uart3 {
				nvidia,pins = "drive_uart3";
				nvidia,high-speed-mode = <TEGRA_PIN_DISABLE>;
				nvidia,schmitt = <TEGRA_PIN_ENABLE>;
				nvidia,low-power-mode = <3>;
				nvidia,pull-down-strength = <31>;
				nvidia,pull-up-strength = <31>;
				nvidia,slew-rate-rising = <TEGRA_PIN_SLEW_RATE_FASTEST>;
				nvidia,slew-rate-falling = <TEGRA_PIN_SLEW_RATE_FASTEST>;
			};
			drive_sdio1 {
				nvidia,pins = "drive_sdio1";
				nvidia,high-speed-mode = <TEGRA_PIN_DISABLE>;
				nvidia,schmitt = <TEGRA_PIN_DISABLE>;
				//nvidia,low-power-mode = <3>;			// N/A
				nvidia,pull-down-strength = <46>;
				nvidia,pull-up-strength = <42>;
				nvidia,slew-rate-rising = <TEGRA_PIN_SLEW_RATE_FAST>;
				nvidia,slew-rate-falling = <TEGRA_PIN_SLEW_RATE_FAST>;
			};
			drive_sdio3 {
				nvidia,pins = "drive_sdio3";
				nvidia,high-speed-mode = <TEGRA_PIN_DISABLE>;
				nvidia,schmitt = <TEGRA_PIN_DISABLE>;
				//nvidia,low-power-mode = <3>;			// N/A
				nvidia,pull-down-strength = <46>;
				nvidia,pull-up-strength = <42>;
				nvidia,slew-rate-rising = <TEGRA_PIN_SLEW_RATE_FAST>;
				nvidia,slew-rate-falling = <TEGRA_PIN_SLEW_RATE_FAST>;
			};
			drive_gma {
				nvidia,pins = "drive_gma";
				//nvidia,high-speed-mode = <TEGRA_PIN_DISABLE>;	// N/A
				//nvidia,schmitt = <TEGRA_PIN_DISABLE>;		// N/A
				//nvidia,low-power-mode = <3>;			// N/A
				nvidia,pull-down-strength = <9>;
				nvidia,pull-up-strength = <9>;
				nvidia,slew-rate-rising = <TEGRA_PIN_SLEW_RATE_SLOWEST>;
				nvidia,slew-rate-falling = <TEGRA_PIN_SLEW_RATE_SLOWEST>;
			};
			drive_gmb {
				nvidia,pins = "drive_gmb";
				//nvidia,high-speed-mode = <TEGRA_PIN_DISABLE>;	// N/A
				//nvidia,schmitt = <TEGRA_PIN_DISABLE>;		// N/A
				//nvidia,low-power-mode = <3>;			// N/A
				nvidia,pull-down-strength = <9>;
				nvidia,pull-up-strength = <9>;
				nvidia,slew-rate-rising = <TEGRA_PIN_SLEW_RATE_SLOWEST>;
				nvidia,slew-rate-falling = <TEGRA_PIN_SLEW_RATE_SLOWEST>;
			};
			drive_gmc {
				nvidia,pins = "drive_gmc";
				//nvidia,high-speed-mode = <TEGRA_PIN_DISABLE>;	// N/A
				//nvidia,schmitt = <TEGRA_PIN_DISABLE>;		// N/A
				//nvidia,low-power-mode = <3>;			// N/A
				nvidia,pull-down-strength = <9>;
				nvidia,pull-up-strength = <9>;
				nvidia,slew-rate-rising = <TEGRA_PIN_SLEW_RATE_SLOWEST>;
				nvidia,slew-rate-falling = <TEGRA_PIN_SLEW_RATE_SLOWEST>;
			};
			drive_gmd {
				nvidia,pins = "drive_gmd";
				//nvidia,high-speed-mode = <TEGRA_PIN_DISABLE>;	// N/A
				//nvidia,schmitt = <TEGRA_PIN_DISABLE>;		// N/A
				//nvidia,low-power-mode = <3>;			// N/A
				nvidia,pull-down-strength = <9>;
				nvidia,pull-up-strength = <9>;
				nvidia,slew-rate-rising = <TEGRA_PIN_SLEW_RATE_SLOWEST>;
				nvidia,slew-rate-falling = <TEGRA_PIN_SLEW_RATE_SLOWEST>;
			};
		};
	};

//	serial@70006000 {
//		status = "okay";
//	};

// I2C1
	i2c@7000c000 {
		status = "okay";
		clock-frequency = <100000>;

		gyrometer@68 {
			compatible = "invn,mpu3050";
			reg = <0x68>;
			interrupt-parent = <&gpio>;
			interrupts = <TEGRA_GPIO(Z, 4) IRQ_TYPE_LEVEL_HIGH>;
		};
	};

// I2C2
	i2c@7000c400 {
		status = "okay";
		clock-frequency = <100000>;
	};

// I2C3
	i2c@7000c500 {
		status = "okay";
		clock-frequency = <100000>;
	};

// I2C4
	hdmiddc: i2c@7000c700 {
		status = "okay";
		clock-frequency = <10000>;
	};

// I2C5
	i2c@7000d000 {
		status = "okay";
		clock-frequency = <400000>;

		pmic: max77612@3c {
			compatible = "maxim,max77663";
			reg = <0x3c>;
			interrupts = <0 86 IRQ_TYPE_LEVEL_HIGH>;
			#interrupt-cells = <2>;
			interrupt-controller;

			gpio-controller;
			#gpio-cells = <2>;

			maxim,enable-clock32k-out;
//			maxim,system-pmic-power-off;
//			maxim,hot-die-threshold-temp = <110000>;

			#thermal-sensor-cells = <0>;

			pinctrl-names = "default";
			pinctrl-0 = <&max77620_default>;
			max77620_default: pinmux@0 {
				pin_gpio0 {
					pins = "gpio0";
					function = "gpio";
					drive-push-pull = <1>;
				};
				pin_gpio1 {
					pins = "gpio1";
					function = "gpio";
				};
				pin_gpio2 {
					pins = "gpio2";
					function = "gpio";
					drive-open-drain = <1>;
				};
				pin_gpio3 {
					pins = "gpio3";
					function = "fps-out";
					drive-open-drain = <1>;
				};
				pin_gpio4 {
					pins = "gpio4";
					function = "32k-out1";
					drive-push-pull = <1>;
				};
				pin_gpio5 {
					pins = "gpio5";
					function = "gpio";
					drive-push-pull = <1>;
				};
				pin_gpio6 {
					pins = "gpio6";
					function = "gpio";
				};
				pin_gpio7 {
					pins = "gpio7";
					function = "gpio";
					drive-open-drain = <1>;
				};
			};

			gpio0 {
				gpio-hog;
				gpios = <0 GPIO_ACTIVE_HIGH>;
				output-low;
				//line-name = "";
			};
			gpio1 {
				gpio-hog;
				gpios = <1 GPIO_ACTIVE_HIGH>;
				input;
				//line-name = "";
			};
			gpio2 {
				gpio-hog;
				gpios = <2 GPIO_ACTIVE_HIGH>;
				opendrain-output-high;
				line-name = "fixed_reg_en_avdd_hdmi_usb_a01";
			};
			gpio3 {
				gpio-hog;
				gpios = <3 GPIO_ACTIVE_HIGH>;
				opendrain-output-low;
				line-name = "fixed_reg_en_3v3_sys_a01";
			};
			gpio4 {
				gpio-hog;
				gpios = <4 GPIO_ACTIVE_HIGH>;
				output-high;
				//line-name = "";
			};
			gpio5 {
				gpio-hog;
				gpios = <5 GPIO_ACTIVE_HIGH>;
				output-low;
				//line-name = "";
			};
			gpio6 {
				gpio-hog;
				gpios = <6 GPIO_ACTIVE_HIGH>;
				input;
				//line-name = "";
			};
			gpio7 {
				gpio-hog;
				gpios = <7 GPIO_ACTIVE_HIGH>;
				opendrain-output-low;
				line-name = "statled";
			};

			fps {
				#address-cells = <1>;
				#size-cells = <0>;
				fps0 {
					maxim,shutdown-fps-time-period-us = <2560>;
					maxim,fps-event-source = <MAX77620_FPS_EVENT_SRC_EN0>;
				};
				fps1 {
					maxim,shutdown-fps-time-period-us = <2560>;
					maxim,fps-event-source = <MAX77620_FPS_EVENT_SRC_EN1>;
				};
				fps2 {
					maxim,shutdown-fps-time-period-us = <1280>;
					maxim,fps-event-source = <MAX77620_FPS_EVENT_SRC_EN0>;
				};
			};

//			watchdog {
//				maxim,wdt-timeout = <16>;
//				maxim,wdt-clear-time = <13>;
//				status = "disabled";
//			};

//			backup-battery {
//				maxim,backup-battery-charging-current = <100>;
//				maxim,backup-battery-charging-voltage = <3000000>;
//				maxim,backup-battery-output-resistor = <100>;
//			};

			regulators {
//				in-ldo0-1-supply = <&max77620_sd3>;
//				in-ldo7-8-supply = <&max77620_sd3>;
//				max77620_sd0: sd0 {
//					regulator-name = "vdd_core";
//					regulator-min-microvolt = <600000>;
//					regulator-max-microvolt = <3387500>;
//					regulator-enable-ramp-delay = <146>;
//					regulator-disable-ramp-delay = <4080>;
//					regulator-ramp-delay = <27500>;
//					regulator-ramp-delay-scale = <300>;
//					regulator-boot-on;
//					regulator-always-on;
//					maxim,fps-source = <FPS_SRC_1>;
//				};
//				max77620_sd1: sd1 {
//					regulator-name = "vddio-ddr";
//					regulator-always-on;
//					regulator-boot-on;
//					maxim,fps-source = <FPS_SRC_0>;
//					regulator-enable-ramp-delay = <130>;
//					regulator-disable-ramp-delay = <145800>;
//					regulator-ramp-delay = <27500>;
//					regulator-ramp-delay-scale = <300>;
//				};
//				max77620_sd2: sd2 {
//					regulator-name = "vdd_gen1v8";
//					regulator-min-microvolt = <1800000>;
//					regulator-max-microvolt = <1800000>;
//					regulator-always-on;
//					maxim,fps-source = <MAX77620_FPS_SRC_0>;
//				};
//				max77620_sd3: sd3 {
//					regulator-name = "vdd_ddr3l_1v35";
//					regulator-min-microvolt = <600000>;
//					regulator-max-microvolt = <3387500>;
//					regulator-always-on;
//					maxim,fps-source = <MAX77620_FPS_SRC_0>;
//				};
//				max77620_ldo0: ldo0 {
//					regulator-name = "avdd-sys";
//					regulator-min-microvolt = <1200000>;
//					regulator-max-microvolt = <1200000>;
//					regulator-enable-ramp-delay = <26>;
//					regulator-disable-ramp-delay = <626>;
//					regulator-ramp-delay = <100000>;
//					regulator-ramp-delay-scale = <200>;
//					regulator-boot-on;
//					maxim,fps-source = <FPS_SRC_NONE>;
//				};
//				max77620_ldo1: ldo1 {
//					regulator-name = "vdd-pex";
//					regulator-min-microvolt = <1075000>;
//					regulator-max-microvolt = <1075000>;
//					regulator-enable-ramp-delay = <22>;
//					regulator-disable-ramp-delay = <630>;
//					regulator-ramp-delay = <100000>;
//					regulator-ramp-delay-scale = <200>;
//					maxim,fps-source = <FPS_SRC_NONE>;
//				};
//				max77620_ldo2: ldo2 {
//					regulator-name = "vddio-sdmmc3";
//					regulator-min-microvolt = <1800000>;
//					regulator-max-microvolt = <3300000>;
//					regulator-enable-ramp-delay = <62>;
//					regulator-disable-ramp-delay = <650>;
//					regulator-ramp-delay = <100000>;
//					regulator-ramp-delay-scale = <200>;
//					maxim,fps-source = <FPS_SRC_NONE>;
//				};
//				max77620_ldo3: ldo3 {
//					regulator-name = "vdd-cam-hv";
//					regulator-min-microvolt = <2800000>;
//					regulator-max-microvolt = <2800000>;
//					regulator-enable-ramp-delay = <50>;
//					regulator-disable-ramp-delay = <1110>;
//					regulator-ramp-delay = <100000>;
//					regulator-ramp-delay-scale = <200>;
//					maxim,fps-source = <FPS_SRC_NONE>;
//				};
//				max77620_ldo4: ldo4 {
//					regulator-name = "vdd-rtc";
//					regulator-min-microvolt = <850000>;
//					regulator-max-microvolt = <850000>;
//					regulator-enable-ramp-delay = <22>;
//					regulator-disable-ramp-delay = <610>;
//					regulator-ramp-delay = <100000>;
//					regulator-ramp-delay-scale = <200>;
//					regulator-always-on;
//					regulator-boot-on;
//					maxim,fps-source = <FPS_SRC_0>;
//				};
//				max77620_ldo5: ldo5 {
//					regulator-name = "avdd-ts-hv";
//					regulator-min-microvolt = <3300000>;
//					regulator-max-microvolt = <3300000>;
//					regulator-enable-ramp-delay = <62>;
//					regulator-disable-ramp-delay = <640>;
//					regulator-ramp-delay = <100000>;
//					regulator-ramp-delay-scale = <200>;
//					maxim,fps-source = <FPS_SRC_NONE>;
//				};
//				max77620_ldo6: ldo6 {
//					regulator-name = "vdd-ts";
//					regulator-min-microvolt = <1800000>;
//					regulator-max-microvolt = <1800000>;
//					regulator-enable-ramp-delay = <36>;
//					regulator-disable-ramp-delay = <674>;
//					regulator-ramp-delay = <100000>;
//					regulator-ramp-delay-scale = <200>;
//					regulator-always-on;
//					regulator-boot-on;
//					maxim,fps-source = <FPS_SRC_0>;
//					maxim,fps-power-up-period = <7>;
//					maxim,fps-power-down-period = <0>;
//				};
//				max77620_ldo7: ldo7 {
//					regulator-name = "vdd-gen-pll-edp";
//					regulator-min-microvolt = <1050000>;
//					regulator-max-microvolt = <1050000>;
//					regulator-enable-ramp-delay = <24>;
//					regulator-disable-ramp-delay = <2768>;
//					regulator-ramp-delay = <100000>;
//					regulator-ramp-delay-scale = <200>;
//					regulator-always-on;
//					regulator-boot-on;
//					maxim,fps-source = <FPS_SRC_1>;
//				};
//				max77620_ldo8: ldo8 {
//					regulator-name = "vdd-hdmi-dp";
//					regulator-min-microvolt = <1050000>;
//					regulator-max-microvolt = <1050000>;
//					regulator-enable-ramp-delay = <22>;
//					regulator-disable-ramp-delay = <1160>;
//					regulator-ramp-delay = <100000>;
//					regulator-ramp-delay-scale = <200>;
//					regulator-boot-on;
//					maxim,fps-source = <FPS_SRC_NONE>;
//				};
			};
		};

///////////////////////////////////////////////////////////////////////////////////////////////////////////
///////////////////////////////////////////////////////////////////////////////////////////////////////////
//		rt5640: rt5640@1c {
//			compatible = "realtek,rt5640";
//			reg = <0x1c>;
//			interrupt-parent = <&gpio>;
//			interrupts = <TEGRA_GPIO(X, 3) IRQ_TYPE_EDGE_FALLING>;
//			realtek,ldo1-en-gpios =
//				<&gpio TEGRA_GPIO(X, 2) GPIO_ACTIVE_HIGH>;
//		};
//
//		pmic: tps65911@2d {
//			compatible = "ti,tps65911";
//			reg = <0x2d>;
//
//			interrupts = <GIC_SPI 86 IRQ_TYPE_LEVEL_HIGH>;
//			#interrupt-cells = <2>;
//			interrupt-controller;
//
//			ti,system-power-controller;
//
//			#gpio-cells = <2>;
//			gpio-controller;
//
//			vcc1-supply = <&vdd_5v_in_reg>;
//			vcc2-supply = <&vdd_5v_in_reg>;
//			vcc3-supply = <&vio_reg>;
//			vcc4-supply = <&vdd_5v_in_reg>;
//			vcc5-supply = <&vdd_5v_in_reg>;
//			vcc6-supply = <&vdd2_reg>;
//			vcc7-supply = <&vdd_5v_in_reg>;
//			vccio-supply = <&vdd_5v_in_reg>;
//
//			regulators {
//				vdd1_reg: vdd1 {
//					regulator-name = "vddio_ddr_1v2";
//					regulator-min-microvolt = <1200000>;
//					regulator-max-microvolt = <1200000>;
//					regulator-always-on;
//				};
//
//				vdd2_reg: vdd2 {
//					regulator-name = "vdd_1v5_gen";
//					regulator-min-microvolt = <1500000>;
//					regulator-max-microvolt = <1500000>;
//					regulator-always-on;
//				};
//
//				vddctrl_reg: vddctrl {
//					regulator-name = "vdd_cpu,vdd_sys";
//					regulator-min-microvolt = <1000000>;
//					regulator-max-microvolt = <1000000>;
//					regulator-always-on;
//				};
//
//				vio_reg: vio {
//					regulator-name = "vdd_1v8_gen";
//					regulator-min-microvolt = <1800000>;
//					regulator-max-microvolt = <1800000>;
//					regulator-always-on;
//				};
//
//				ldo1_reg: ldo1 {
//					regulator-name = "vdd_pexa,vdd_pexb";
//					regulator-min-microvolt = <1050000>;
//					regulator-max-microvolt = <1050000>;
//				};
//
//				ldo2_reg: ldo2 {
//					regulator-name = "vdd_sata,avdd_plle";
//					regulator-min-microvolt = <1050000>;
//					regulator-max-microvolt = <1050000>;
//				};
//
//				/* LDO3 is not connected to anything */
//
//				ldo4_reg: ldo4 {
//					regulator-name = "vdd_rtc";
//					regulator-min-microvolt = <1200000>;
//					regulator-max-microvolt = <1200000>;
//					regulator-always-on;
//				};
//
//				ldo5_reg: ldo5 {
//					regulator-name = "vddio_sdmmc,avdd_vdac";
//					regulator-min-microvolt = <1800000>;
//					regulator-max-microvolt = <3300000>;
//					regulator-always-on;
//				};
//
//				ldo6_reg: ldo6 {
//					regulator-name = "avdd_dsi_csi,pwrdet_mipi";
//					regulator-min-microvolt = <1200000>;
//					regulator-max-microvolt = <1200000>;
//				};
//
//				ldo7_reg: ldo7 {
//					regulator-name = "vdd_pllm,x,u,a_p_c_s";
//					regulator-min-microvolt = <1200000>;
//					regulator-max-microvolt = <1200000>;
//					regulator-always-on;
//				};
//
//				ldo8_reg: ldo8 {
//					regulator-name = "vdd_ddr_hs";
//					regulator-min-microvolt = <1000000>;
//					regulator-max-microvolt = <1000000>;
//					regulator-always-on;
//				};
//			};
//		};
//
//		tps62361@60 {
//			compatible = "ti,tps62361";
//			reg = <0x60>;
//
//			regulator-name = "tps62361-vout";
//			regulator-min-microvolt = <500000>;
//			regulator-max-microvolt = <1500000>;
//			regulator-boot-on;
//			regulator-always-on;
//			ti,vsel0-state-high;
//			ti,vsel1-state-high;
//		};
	};

// Tegra Power Management Controller
	pmc@7000e400 {
		status = "okay";
		nvidia,invert-interrupt;				// The signal is active low, so must be inverted
//		nvidia,suspend-mode = <1>;
//		nvidia,cpu-pwr-good-time = <2000>;
//		nvidia,cpu-pwr-off-time = <200>;
//		nvidia,core-pwr-good-time = <3845 3845>;
//		nvidia,core-pwr-off-time = <0>;
//		nvidia,core-power-req-active-high;
//		nvidia,sys-clock-req-active-high;
	};

	regulators {
		compatible = "simple-bus";
		#address-cells = <1>;
		#size-cells = <0>;

// Temporary regulator for vin-supply
		vdd_3v3_main_reg: regulator@0 {
			compatible = "regulator-fixed";
			reg = <0>;
			regulator-name = "vdd_3v3_main_reg";
			regulator-min-microvolt = <3387500>;
			regulator-max-microvolt = <3387500>;
			regulator-always-on;
		};

//// LVDS analogue supply
//		vdd_lvds_areg: regulator@1 {
//			compatible = "regulator-fixed";
//			reg = <1>;
//			regulator-name = "vdd_lvds_areg";
//			regulator-min-microvolt = <3300000>;
//			regulator-max-microvolt = <3300000>;
//			gpio = <&gpio TEGRA_GPIO(H, 2) GPIO_ACTIVE_HIGH>;
//			regulator-boot-on;
//			enable-active-high;
//			vin-supply = <&vdd_3v3_main_reg>;
//		};

//// LVDS digital supply
//		vdd_lvds_dreg: regulator@2 {
//			compatible = "regulator-fixed";
//			reg = <2>;
//			regulator-name = "vdd_lvds_dreg";
//			regulator-min-microvolt = <3300000>;
//			regulator-max-microvolt = <3300000>;
//			gpio = <&gpio TEGRA_GPIO(W, 1) GPIO_ACTIVE_HIGH>;
//			regulator-boot-on;
//			enable-active-high;
//			vin-supply = <&vdd_3v3_main_reg>;
//		};

//		chargepump_5v_reg: regulator@1 {
//			compatible = "regulator-fixed";
//			reg = <1>;
//			regulator-name = "chargepump_5v";
//			regulator-min-microvolt = <5000000>;
//			regulator-max-microvolt = <5000000>;
//			regulator-boot-on;
//			regulator-always-on;
//			enable-active-high;
//			gpio = <&pmic 0 GPIO_ACTIVE_HIGH>;
//		};
//
//		ddr_reg: regulator@2 {
//			compatible = "regulator-fixed";
//			reg = <2>;
//			regulator-name = "vdd_ddr";
//			regulator-min-microvolt = <1500000>;
//			regulator-max-microvolt = <1500000>;
//			regulator-always-on;
//			regulator-boot-on;
//			enable-active-high;
//			gpio = <&pmic 7 GPIO_ACTIVE_HIGH>;
//			vin-supply = <&vdd_5v_in_reg>;
//		};
//
//		vdd_5v_sata_reg: regulator@3 {
//			compatible = "regulator-fixed";
//			reg = <3>;
//			regulator-name = "vdd_5v_sata";
//			regulator-min-microvolt = <5000000>;
//			regulator-max-microvolt = <5000000>;
//			regulator-always-on;
//			regulator-boot-on;
//			enable-active-high;
//			gpio = <&gpio TEGRA_GPIO(D, 6) GPIO_ACTIVE_HIGH>;
//			vin-supply = <&vdd_5v_in_reg>;
//		};
//
//		usb1_vbus_reg: regulator@4 {
//			compatible = "regulator-fixed";
//			reg = <4>;
//			regulator-name = "usb1_vbus";
//			regulator-min-microvolt = <5000000>;
//			regulator-max-microvolt = <5000000>;
//			enable-active-high;
//			gpio = <&gpio TEGRA_GPIO(DD, 6) GPIO_ACTIVE_HIGH>;
//			gpio-open-drain;
//			vin-supply = <&vdd_5v_in_reg>;
//		};
//
//		usb3_vbus_reg: regulator@5 {
//			compatible = "regulator-fixed";
//			reg = <5>;
//			regulator-name = "usb3_vbus";
//			regulator-min-microvolt = <5000000>;
//			regulator-max-microvolt = <5000000>;
//			enable-active-high;
//			gpio = <&gpio TEGRA_GPIO(DD, 4) GPIO_ACTIVE_HIGH>;
//			gpio-open-drain;
//			vin-supply = <&vdd_5v_in_reg>;
//		};
//
//		sys_3v3_reg: regulator@6 {
//			compatible = "regulator-fixed";
//			reg = <6>;
//			regulator-name = "sys_3v3,vdd_3v3_alw";
//			regulator-min-microvolt = <3300000>;
//			regulator-max-microvolt = <3300000>;
//			regulator-always-on;
//			regulator-boot-on;
//			enable-active-high;
//			gpio = <&pmic 6 GPIO_ACTIVE_HIGH>;
//			vin-supply = <&vdd_5v_in_reg>;
//		};
//
//		sys_3v3_pexs_reg: regulator@7 {
//			compatible = "regulator-fixed";
//			reg = <7>;
//			regulator-name = "sys_3v3_pexs";
//			regulator-min-microvolt = <3300000>;
//			regulator-max-microvolt = <3300000>;
//			regulator-always-on;
//			regulator-boot-on;
//			enable-active-high;
//			gpio = <&gpio TEGRA_GPIO(L, 7) GPIO_ACTIVE_HIGH>;
//			vin-supply = <&sys_3v3_reg>;
//		};
//
//		vdd_5v0_hdmi: regulator@8 {
//			compatible = "regulator-fixed";
//			reg = <8>;
//			regulator-name = "+VDD_5V_HDMI";
//			regulator-min-microvolt = <5000000>;
//			regulator-max-microvolt = <5000000>;
//			regulator-always-on;
//			regulator-boot-on;
//			vin-supply = <&sys_3v3_reg>;
//		};
	};

//	spi@7000da00 {
//		status = "okay";
//		spi-max-frequency = <25000000>;
//		spi-flash@1 {
//			compatible = "winbond,w25q32";
//			reg = <1>;
//			spi-max-frequency = <20000000>;
//		};
//	};

//	ahub@70080000 {
//		i2s@70080400 {
//			status = "okay";
//		};
//	};

//	sdhci@78000000 {
//		status = "okay";
//		vqmmc-supply = <&ldo5_reg>;
//		cd-gpios = <&gpio TEGRA_GPIO(I, 5) GPIO_ACTIVE_LOW>;
//		wp-gpios = <&gpio TEGRA_GPIO(T, 3) GPIO_ACTIVE_HIGH>;
//		power-gpios = <&gpio TEGRA_GPIO(D, 7) GPIO_ACTIVE_HIGH>;
//		bus-width = <4>;
//	};

//	sdhci@78000600 {
//		#address-cells = <1>;
//		#size-cells = <0>;
//
//		status = "okay";
//		bus-width = <8>;
//		non-removable;
//		mmc-ddr-1_8v;
//		mmc-hs400-1_8v;
//
//		mmccard: mmccard@0 {
//			reg = <0>;
//			compatible = "mmc-card";
//			broken-hpi;
//		};
//	};

//	usb@7d000000 {
//		compatible = "nvidia,tegra30-udc";
//		status = "okay";
//		dr_mode = "peripheral";
//	};

//	usb-phy@7d000000 {
//		status = "okay";
//	};

//	usb@7d004000 {
//		status = "okay";
//	};

//	phy2: usb-phy@7d004000 {
//		vbus-supply = <&sys_3v3_reg>;
//		status = "okay";
//	};

//	usb@7d008000 {
//		status = "okay";
//	};

//	usb-phy@7d008000 {
//		vbus-supply = <&usb3_vbus_reg>;
//		status = "okay";
//	};

// PWM controller
//  - Backlight
	pwm@7000a000 {
		status = "okay";
	};

	lcd_backlight: backlight {
		compatible = "pwm-backlight";

		enable-gpios = <&gpio TEGRA_GPIO(H, 3) GPIO_ACTIVE_HIGH>;
		power-supply = <&vdd_3v3_main_reg>;
		pwms = <&pwm 0 5000000>;

		default-brightness-level = <30>;
		brightness-levels =
			<  0   1   2   3   4   5   6   7
			   7   8   9  10  11  12  13  14
			  15  16  17  18  19  20  20  21
			  22  23  24  25  26  27  28  29
			  30  31  32  32  34  34  36  36
			  38  39  40  40  41  42  42  43
			  44  44  45  46  46  47  48  48
			  49  50  50  51  52  53  54  54
			  55  56  57  58  58  59  60  61
			  62  63  64  65  66  67  68  69
			  70  71  72  72  73  74  75  76
			  76  77  78  79  80  81  82  83
			  85  86  87  89  90  91  92  92
			  93  94  95  96  96  97  98  99
			 100 100 101 102 103 104 104 105
			 106 107 108 108 109 110 112 114
			 116 118 120 121 122 123 124 125
			 126 127 128 129 130 131 132 133
			 134 135 136 137 138 139 140 141
			 142 143 144 145 146 147 148 149
			 150 151 151 152 153 153 154 155
			 155 156 157 157 158 159 159 160
			 162 164 166 168 170 172 174 176
			 178 180 181 181 182 183 183 184
			 185 185 186 187 187 188 189 189
			 190 191 192 193 194 195 196 197
			 198 199 200 201 201 202 203 203
			 204 205 205 206 207 207 208 209
			 209 210 211 211 212 212 213 213
			 214 215 215 216 216 217 217 218
			 219 219 220 222 226 230 232 234
			 236 238 240 244 248 251 253 255>;
	};

	host1x@50000000 {
// LCD
                dc@54200000 {
			rgb {
				status = "okay";
				nvidia,panel = <&wikipad_lcd>;
			};

			port@0 {
				dc_rgb_output: endpoint {
					remote-endpoint = <&lvds_enc_in>;
					//bus-width = <16>;
				};
			};
		};

// HDMI out
//		hdmi@54280000 {
//			status = "okay";
//
//			hdmi-supply = <&vdd_5v0_hdmi>;
//			vdd-supply = <&sys_3v3_reg>;
//			pll-supply = <&vio_reg>;
//
//			nvidia,hpd-gpio =
//				<&gpio TEGRA_GPIO(N, 7) GPIO_ACTIVE_HIGH>;
//			nvidia,ddc-i2c-bus = <&hdmiddc>;
//		};
	};

// SN75LVDS83B
	lvds-encoder {
		compatible = "lvds-encoder";
		#address-cells = <1>;
		#size-cells = <0>;

		ports {
			#address-cells = <1>;
			#size-cells = <0>;

			port@0 {
				reg = <0>;

				lvds_enc_in: endpoint {
					remote-endpoint = <&dc_rgb_output>;
				};
			};

			port@1 {
				reg = <1>;

				lvds_enc_out: endpoint {
					remote-endpoint = <&wikipad_lcd_in>;
				};
			};
		};
	};

	wikipad_lcd: panel {
		compatible = "wikipad7,lcd", "panel-lvds";

		width-mm = <151>;
		height-mm = <94>;

		data-mapping = "jeida-18";
		//power-supply1 = <&vdd_lvds_areg>;					// Fudged driver to implement multiple rails
		//power-supply2 = <&vdd_lvds_dreg>;
		enable-gpios = <&gpio TEGRA_GPIO(N, 6) GPIO_ACTIVE_HIGH>;		// Actually implemented on the LVDS encoder

		backlight = <&lcd_backlight>;

		panel-timing {
			/* 800x1280 @60Hz */
			clock-frequency = <81750000>;
			hsync-len = <64>;
			vsync-len = <1>;
			hback-porch = <128>;
			vback-porch = <2>;
			hactive = <800>;
			vactive = <1280>;
			hfront-porch = <64>;
			vfront-porch = <5>;
		};

		port {
			wikipad_lcd_in: endpoint {
				remote-endpoint = <&lvds_enc_out>;
			};
		};
	};

//	sound {
//		compatible = "nvidia,tegra-audio-rt5640-beaver",
//			     "nvidia,tegra-audio-rt5640";
//		nvidia,model = "NVIDIA Tegra Beaver";
//
//		nvidia,audio-routing =
//			"Headphones", "HPOR",
//			"Headphones", "HPOL",
//			"Mic Jack", "MICBIAS1",
//			"IN2P", "Mic Jack";
//
//		nvidia,i2s-controller = <&tegra_i2s1>;
//		nvidia,audio-codec = <&rt5640>;
//
//		nvidia,hp-det-gpios = <&gpio TEGRA_GPIO(W, 2) GPIO_ACTIVE_HIGH>;
//
//		clocks = <&tegra_car TEGRA30_CLK_PLL_A>,
//			 <&tegra_car TEGRA30_CLK_PLL_A_OUT0>,
//			 <&tegra_car TEGRA30_CLK_EXTERN1>;
//		clock-names = "pll_a", "pll_a_out0", "mclk";
//	};

// Max77620 thermal zone
	cool_dev: cool-dev {
		compatible = "cooling-dev";
		#cooling-cells = <2>;
	};

	thermal-zones {
		PMIC-Die {
			polling-delay = <0>;
			polling-delay-passive = <0>;
			thermal-sensors = <&pmic>;

			trips {
				pmic_die_warn_temp_thresh: hot-die {
					temperature = <120000>;
					type = "hot";
					hysteresis = <0>;
				};

				pmic_die_cirt_temp_thresh: cirtical-die {
					temperature = <140000>;
					type = "critical";
					hysteresis = <0>;
				};
			};

			cooling-maps {
				map0 {
					trip = <&pmic_die_warn_temp_thresh>;
					cooling-device = <&cool_dev THERMAL_NO_LIMIT THERMAL_NO_LIMIT>;
					contribution = <100>;
				};
			};
		};
	};
};
